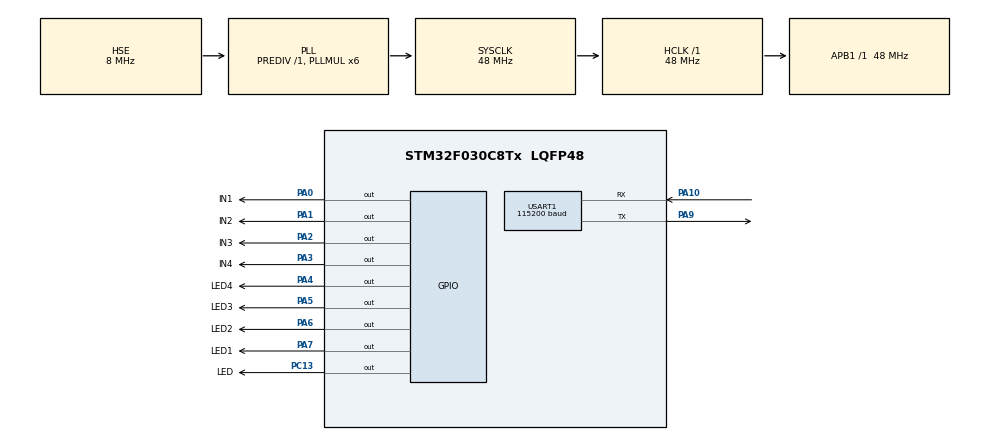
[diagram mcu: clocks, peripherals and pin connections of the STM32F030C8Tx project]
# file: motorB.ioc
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Mcu.Family=STM32F0
Mcu.Name=STM32F030C8Tx
Mcu.Package=LQFP48
NVIC.USART1_IRQn=true\:0\:0\:false\:false\:true\:true\:true
PA0.GPIO_Label=IN1
PA0.GPIO_Speed=GPIO_SPEED_FREQ_HIGH
PA0.PinState=GPIO_PIN_SET
PA0.Signal=GPIO_Output
PA1.GPIO_Label=IN2
PA1.GPIO_Speed=GPIO_SPEED_FREQ_HIGH
PA1.PinState=GPIO_PIN_SET
PA1.Signal=GPIO_Output
PA10.Mode=Asynchronous
PA10.Signal=USART1_RX
PA2.GPIO_Label=IN3
PA2.GPIO_Speed=GPIO_SPEED_FREQ_HIGH
PA2.PinState=GPIO_PIN_SET
PA2.Signal=GPIO_Output
PA3.GPIO_Label=IN4
PA3.GPIO_Speed=GPIO_SPEED_FREQ_HIGH
PA3.PinState=GPIO_PIN_SET
PA3.Signal=GPIO_Output
PA4.GPIO_Label=LED4
PA4.GPIO_Speed=GPIO_SPEED_FREQ_HIGH
PA4.PinState=GPIO_PIN_SET
PA4.Signal=GPIO_Output
PA5.GPIO_Label=LED3
PA5.GPIO_Speed=GPIO_SPEED_FREQ_HIGH
PA5.PinState=GPIO_PIN_SET
PA5.Signal=GPIO_Output
PA6.GPIO_Label=LED2
PA6.GPIO_Speed=GPIO_SPEED_FREQ_HIGH
PA6.PinState=GPIO_PIN_SET
PA6.Signal=GPIO_Output
PA7.GPIO_Label=LED1
PA7.GPIO_Speed=GPIO_SPEED_FREQ_HIGH
PA7.PinState=GPIO_PIN_SET
PA7.Signal=GPIO_Output
PA9.Mode=Asynchronous
PA9.Signal=USART1_TX
PC13.GPIO_Label=LED
PC13.Signal=GPIO_Output
PC14-OSC32_IN.Mode=LSE-External-Oscillator
PC14-OSC32_IN.Signal=RCC_OSC32_IN
PC15-OSC32_OUT.Mode=LSE-External-Oscillator
PC15-OSC32_OUT.Signal=RCC_OSC32_OUT
PF0-OSC_IN.Mode=HSE-External-Oscillator
PF0-OSC_IN.Signal=RCC_OSC_IN
PF1-OSC_OUT.Mode=HSE-External-Oscillator
PF1-OSC_OUT.Signal=RCC_OSC_OUT
ProjectManager.HeapSize=0x200
ProjectManager.StackSize=0x400
ProjectManager.TargetToolchain=MDK-ARM V5
RCC.AHBFreq_Value=48000000
RCC.APB1Freq_Value=48000000
RCC.APB1TimFreq_Value=48000000
RCC.HCLKFreq_Value=48000000
RCC.PLLMUL=RCC_PLL_MUL6
RCC.PLLSourceVirtual=RCC_PLLSOURCE_HSE
RCC.SYSCLKFreq_VALUE=48000000
RCC.SYSCLKSource=RCC_SYSCLKSOURCE_PLLCLK
USART1.BaudRate=115200
USART1.VirtualMode-Asynchronous=VM_ASYNC
board=custom

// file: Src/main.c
/* USER CODE BEGIN Header */
/**
  ******************************************************************************
  * @file           : main.c
  * @brief          : Main program body
  ******************************************************************************
  * @attention
  *
  * <h2><center>&copy; Copyright (c) 2021 STMicroelectronics.
  * All rights reserved.</center></h2>
  *
  * This software component is licensed by ST under BSD 3-Clause license,
  * the "License"; You may not use this file except in compliance with the
  * License. You may obtain a copy of the License at:
  *                        opensource.org/licenses/BSD-3-Clause
  *
  ******************************************************************************
  */
/* USER CODE END Header */

#include "main.h"
#include "usart.h"
#include "gpio.h"
#include "stdio.h"
#include "motor.h"
#include "led.h"

void SystemClock_Config(void);

int main(void)
{
  /* USER CODE BEGIN 1 */
	uint8_t ch;
  /* USER CODE END 1 */

  /* MCU Configuration--------------------------------------------------------*/

  /* Reset of all peripherals, Initializes the Flash interface and the Systick. */
  HAL_Init();

  /* Configure the system clock */
  SystemClock_Config();

  /* Initialize all configured peripherals */
  MX_GPIO_Init();
  MX_USART1_UART_Init();
  /* USER CODE BEGIN 2 */
  motor_init();
  led_init();
  /* USER CODE END 2 */

  /* Infinite loop */
  while (1)
  {
	ch = getchar();
	  switch(ch) {
/****************KEY*******************/
		  case '0':{
					led_station(key,open);
					motor_open();
					led_station(key,close);

		  };break;
		  case '1':{
					led_station(key,open);
					motor_close();
					led_station(key,close);

		  };break;
/*****************RAIN******************/
		  case '2':{
					led_station(rain,open);
					motor_open();
					led_station(rain,close);

		  };break;
		  case '3':{
					led_station(rain,open);
					motor_close();
					led_station(rain,close);

		  };break;
/*****************INFRARED******************/
		  case '4':{
					led_station(infrared,open);
					motor_open();
					led_station(infrared,close);

		  };break;
		  case '5':{
					led_station(infrared,open);
					motor_close();
					led_station(infrared,close);

		  };break;
/******************SMOKE*****************/
		  case '6':{
					led_station(smoke,open);
					motor_open();
					led_station(smoke,close);

		  };break;
		  case '7':{
					led_station(smoke,open);
					motor_close();
					led_station(smoke,close);

		  };break;

		default:
			break;
	  };

  }
}

void SystemClock_Config(void)
{
  RCC_OscInitTypeDef RCC_OscInitStruct = {0};
  RCC_ClkInitTypeDef RCC_ClkInitStruct = {0};
  RCC_PeriphCLKInitTypeDef PeriphClkInit = {0};

  /** Initializes the CPU, AHB and APB busses clocks
  */
  RCC_OscInitStruct.OscillatorType = RCC_OSCILLATORTYPE_HSE;
  RCC_OscInitStruct.HSEState = RCC_HSE_ON;
  RCC_OscInitStruct.PLL.PLLState = RCC_PLL_ON;
  RCC_OscInitStruct.PLL.PLLSource = RCC_PLLSOURCE_HSE;
  RCC_OscInitStruct.PLL.PLLMUL = RCC_PLL_MUL6;
  RCC_OscInitStruct.PLL.PREDIV = RCC_PREDIV_DIV1;
  if (HAL_RCC_OscConfig(&RCC_OscInitStruct) != HAL_OK)
  {
    Error_Handler();
  }
  /** Initializes the CPU, AHB and APB busses clocks
  */
  RCC_ClkInitStruct.ClockType = RCC_CLOCKTYPE_HCLK|RCC_CLOCKTYPE_SYSCLK
                              |RCC_CLOCKTYPE_PCLK1;
  RCC_ClkInitStruct.SYSCLKSource = RCC_SYSCLKSOURCE_PLLCLK;
  RCC_ClkInitStruct.AHBCLKDivider = RCC_SYSCLK_DIV1;
  RCC_ClkInitStruct.APB1CLKDivider = RCC_HCLK_DIV1;

  if (HAL_RCC_ClockConfig(&RCC_ClkInitStruct, FLASH_LATENCY_1) != HAL_OK)
  {
    Error_Handler();
  }
  PeriphClkInit.PeriphClockSelection = RCC_PERIPHCLK_USART1;
  PeriphClkInit.Usart1ClockSelection = RCC_USART1CLKSOURCE_PCLK1;
  if (HAL_RCCEx_PeriphCLKConfig(&PeriphClkInit) != HAL_OK)
  {
    Error_Handler();
  }
}

void Error_Handler(void)
{
}

/************************ (C) COPYRIGHT STMicroelectronics *****END OF FILE****/
